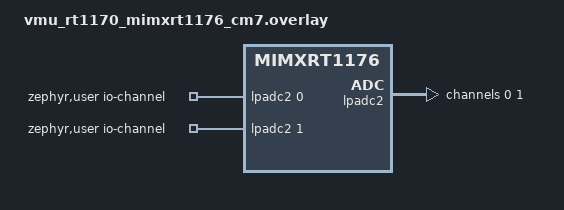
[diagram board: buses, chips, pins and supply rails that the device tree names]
/*
 * SPDX-License-Identifier: Apache-2.0
 *
 * Copyright 2023 CogniPilot Foundation
 */

#include <zephyr/dt-bindings/adc/mcux-lpadc.h>

/ {
	zephyr,user {
		io-channels = <&lpadc2 0>, <&lpadc2 1>;
	};
};

&lpadc2 {
	#address-cells = <1>;
	#size-cells = <0>;

	channel@0 {
		reg = <0>;
		zephyr,gain = "ADC_GAIN_1";
		zephyr,reference = "ADC_REF_EXTERNAL0";
		zephyr,acquisition-time = <ADC_ACQ_TIME_DEFAULT>;
		zephyr,resolution = <12>;
	};

	channel@1 {
		reg = <1>;
		zephyr,gain = "ADC_GAIN_1";
		zephyr,reference = "ADC_REF_EXTERNAL0";
		zephyr,acquisition-time = <ADC_ACQ_TIME_DEFAULT>;
		zephyr,resolution = <12>;
	};
};
